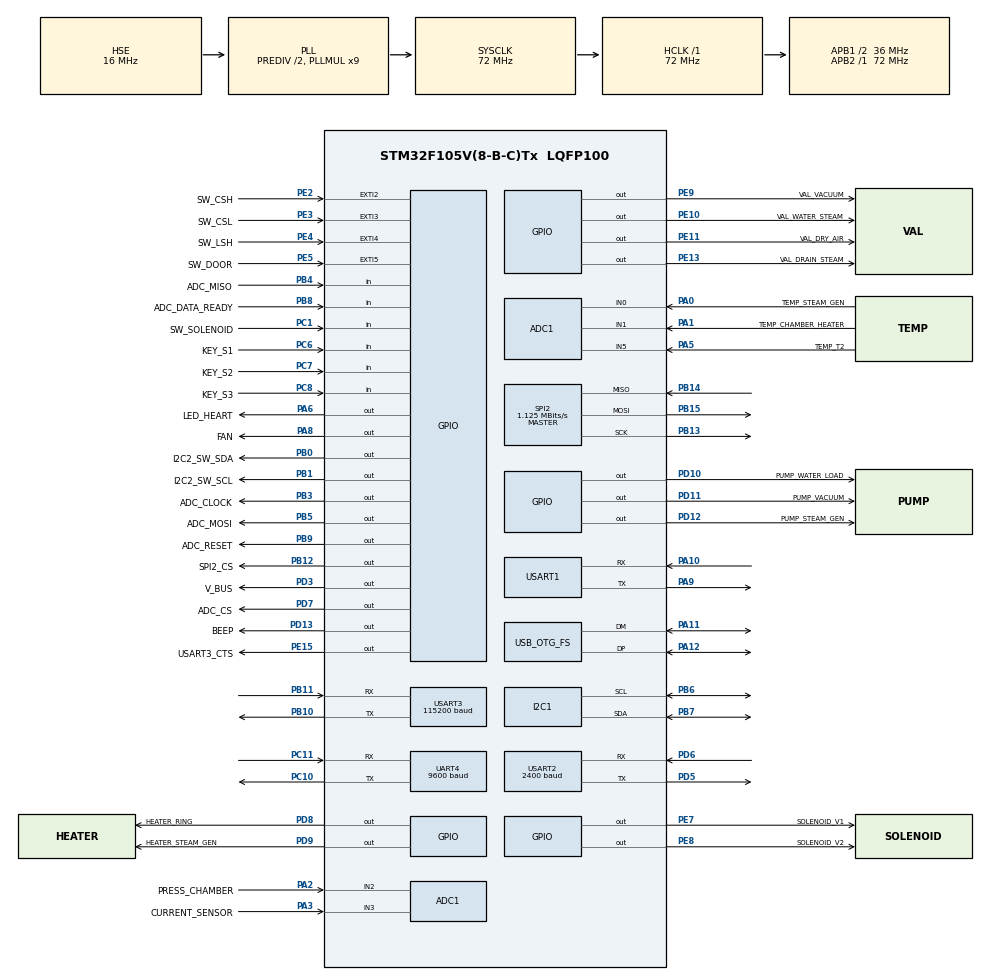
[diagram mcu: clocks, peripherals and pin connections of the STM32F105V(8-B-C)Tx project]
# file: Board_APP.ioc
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ADC1.Channel-0\#ChannelRegularConversion=ADC_CHANNEL_0
ADC1.ContinuousConvMode=DISABLE
ADC1.DiscontinuousConvMode=DISABLE
ADC1.NbrOfConversion=1
ADC1.NbrOfConversionFlag=1
ADC1.Rank-0\#ChannelRegularConversion=1
ADC1.SamplingTime-0\#ChannelRegularConversion=ADC_SAMPLETIME_28CYCLES_5
ADC1.master=1
Dma.Request0=USART1_RX
Dma.Request1=USART3_RX
Dma.Request2=USART3_TX
Dma.USART1_RX.0.Direction=DMA_PERIPH_TO_MEMORY
Dma.USART1_RX.0.Instance=DMA1_Channel5
Dma.USART1_RX.0.MemDataAlignment=DMA_MDATAALIGN_BYTE
Dma.USART1_RX.0.MemInc=DMA_MINC_ENABLE
Dma.USART1_RX.0.Mode=DMA_NORMAL
Dma.USART1_RX.0.PeriphDataAlignment=DMA_PDATAALIGN_BYTE
Dma.USART1_RX.0.PeriphInc=DMA_PINC_DISABLE
Dma.USART1_RX.0.Priority=DMA_PRIORITY_LOW
Dma.USART3_RX.1.Direction=DMA_PERIPH_TO_MEMORY
Dma.USART3_RX.1.Instance=DMA1_Channel3
Dma.USART3_RX.1.MemDataAlignment=DMA_MDATAALIGN_BYTE
Dma.USART3_RX.1.MemInc=DMA_MINC_ENABLE
Dma.USART3_RX.1.Mode=DMA_CIRCULAR
Dma.USART3_RX.1.PeriphDataAlignment=DMA_PDATAALIGN_BYTE
Dma.USART3_RX.1.PeriphInc=DMA_PINC_DISABLE
Dma.USART3_RX.1.Priority=DMA_PRIORITY_HIGH
Dma.USART3_TX.2.Direction=DMA_MEMORY_TO_PERIPH
Dma.USART3_TX.2.Instance=DMA1_Channel2
Dma.USART3_TX.2.MemDataAlignment=DMA_MDATAALIGN_BYTE
Dma.USART3_TX.2.MemInc=DMA_MINC_ENABLE
Dma.USART3_TX.2.Mode=DMA_CIRCULAR
Dma.USART3_TX.2.PeriphDataAlignment=DMA_PDATAALIGN_BYTE
Dma.USART3_TX.2.PeriphInc=DMA_PINC_DISABLE
Dma.USART3_TX.2.Priority=DMA_PRIORITY_HIGH
FATFS._CODE_PAGE=850
FATFS._FS_REENTRANT=0
FATFS._MAX_LFN=32
FATFS._MAX_SS=4096
FATFS._USE_LFN=1
FREERTOS.BinarySemaphores01=semaphorePower,Dynamic,NULL
FREERTOS.Tasks01=taskAlive,-2,2048,StartTaskAlive,Default,NULL,Dynamic,NULL,NULL
FREERTOS.configTOTAL_HEAP_SIZE=42000
FREERTOS.configUSE_NEWLIB_REENTRANT=1
Mcu.Family=STM32F1
Mcu.Name=STM32F105V(8-B-C)Tx
Mcu.Package=LQFP100
NVIC.DMA1_Channel2_IRQn=true\:5\:0\:false\:false\:true\:true\:false\:true\:true
NVIC.DMA1_Channel3_IRQn=true\:5\:0\:false\:false\:true\:true\:false\:true\:true
NVIC.DMA1_Channel5_IRQn=true\:5\:0\:false\:false\:true\:true\:false\:true\:true
NVIC.EXTI3_IRQn=true\:5\:0\:false\:false\:true\:true\:true\:true\:true
NVIC.EXTI4_IRQn=true\:5\:0\:false\:false\:true\:true\:true\:true\:true
NVIC.EXTI9_5_IRQn=true\:5\:0\:false\:false\:true\:true\:true\:true\:true
NVIC.OTG_FS_IRQn=true\:5\:0\:false\:false\:true\:true\:true\:true\:true
NVIC.PriorityGroup=NVIC_PRIORITYGROUP_4
NVIC.TIM2_IRQn=true\:5\:0\:false\:false\:true\:true\:true\:true\:true
NVIC.TIM3_IRQn=true\:5\:0\:false\:false\:true\:true\:true\:true\:true
NVIC.TIM6_IRQn=true\:0\:0\:true\:false\:true\:false\:false\:true\:true
NVIC.TimeBase=TIM6_IRQn
NVIC.TimeBaseIP=TIM6
OSC_IN.Mode=HSE-External-Oscillator
OSC_IN.Signal=RCC_OSC_IN
OSC_OUT.Mode=HSE-External-Oscillator
OSC_OUT.Signal=RCC_OSC_OUT
PA0-WKUP.GPIO_Label=TEMP_STEAM_GEN
PA0-WKUP.Signal=ADCx_IN0
PA1.GPIO_Label=TEMP_CHAMBER_HEATER
PA1.Signal=ADCx_IN1
PA10.Mode=Asynchronous
PA10.Signal=USART1_RX
PA11.Mode=Host_Only
PA11.Signal=USB_OTG_FS_DM
PA12.Mode=Host_Only
PA12.Signal=USB_OTG_FS_DP
PA13.Mode=Serial_Wire
PA13.Signal=SYS_JTMS-SWDIO
PA14.Mode=Serial_Wire
PA14.Signal=SYS_JTCK-SWCLK
PA2.GPIO_Label=PRESS_CHAMBER
PA2.Signal=ADCx_IN2
PA3.GPIO_Label=CURRENT_SENSOR
PA3.Signal=ADCx_IN3
PA5.GPIO_Label=TEMP_T2
PA5.Signal=ADCx_IN5
PA6.GPIO_Label=LED_HEART
PA6.Signal=GPIO_Output
PA8.GPIO_Label=FAN
PA8.Signal=GPIO_Output
PA9.Mode=Asynchronous
PA9.Signal=USART1_TX
PB0.GPIO_Label=I2C2_SW_SDA
PB0.Signal=GPIO_Output
PB1.GPIO_Label=I2C2_SW_SCL
PB1.Signal=GPIO_Output
PB10.Mode=Asynchronous
PB10.Signal=USART3_TX
PB11.Mode=Asynchronous
PB11.Signal=USART3_RX
PB12.GPIO_Label=SPI2_CS
PB12.Signal=GPIO_Output
PB13.Mode=Full_Duplex_Master
PB13.Signal=SPI2_SCK
PB14.Mode=Full_Duplex_Master
PB14.Signal=SPI2_MISO
PB15.Mode=Full_Duplex_Master
PB15.Signal=SPI2_MOSI
PB3.GPIO_Label=ADC_CLOCK
PB3.Signal=GPIO_Output
PB4.GPIO_Label=ADC_MISO
PB4.Signal=GPIO_Input
PB5.GPIO_Label=ADC_MOSI
PB5.Signal=GPIO_Output
PB6.Mode=I2C
PB6.Signal=I2C1_SCL
PB7.Mode=I2C
PB7.Signal=I2C1_SDA
PB8.GPIO_Label=ADC_DATA_READY
PB8.Signal=GPIO_Input
PB9.GPIO_Label=ADC_RESET
PB9.Signal=GPIO_Output
PC1.GPIO_Label=SW_SOLENOID
PC1.Signal=GPIO_Input
PC10.Mode=Asynchronous
PC10.Signal=UART4_TX
PC11.Mode=Asynchronous
PC11.Signal=UART4_RX
PC6.GPIO_Label=KEY_S1
PC6.GPIO_PuPd=GPIO_PULLUP
PC6.Signal=GPIO_Input
PC7.GPIO_Label=KEY_S2
PC7.GPIO_PuPd=GPIO_PULLUP
PC7.Signal=GPIO_Input
PC8.GPIO_Label=KEY_S3
PC8.GPIO_PuPd=GPIO_PULLUP
PC8.Signal=GPIO_Input
PD10.GPIO_Label=PUMP_WATER_LOAD
PD10.Signal=GPIO_Output
PD11.GPIO_Label=PUMP_VACUUM
PD11.Signal=GPIO_Output
PD12.GPIO_Label=PUMP_STEAM_GEN
PD12.Signal=GPIO_Output
PD13.GPIO_Label=BEEP
PD13.Signal=GPIO_Output
PD3.GPIO_Label=V_BUS
PD3.Signal=GPIO_Output
PD5.Mode=Asynchronous
PD5.Signal=USART2_TX
PD6.Mode=Asynchronous
PD6.Signal=USART2_RX
PD7.GPIO_Label=ADC_CS
PD7.Signal=GPIO_Output
PD8.GPIO_Label=HEATER_RING
PD8.Signal=GPIO_Output
PD9.GPIO_Label=HEATER_STEAM_GEN
PD9.Signal=GPIO_Output
PE10.GPIO_Label=VAL_WATER_STEAM
PE10.Signal=GPIO_Output
PE11.GPIO_Label=VAL_DRY_AIR
PE11.Signal=GPIO_Output
PE13.GPIO_Label=VAL_DRAIN_STEAM
PE13.Signal=GPIO_Output
PE15.GPIO_Label=USART3_CTS
PE15.Signal=GPIO_Output
PE2.GPIO_Label=SW_CSH
PE2.GPIO_ModeDefaultEXTI=GPIO_MODE_IT_RISING_FALLING
PE2.Signal=GPXTI2
PE3.GPIO_Label=SW_CSL
PE3.GPIO_ModeDefaultEXTI=GPIO_MODE_IT_RISING_FALLING
PE3.Signal=GPXTI3
PE4.GPIO_Label=SW_LSH
PE4.GPIO_ModeDefaultEXTI=GPIO_MODE_IT_RISING_FALLING
PE4.Signal=GPXTI4
PE5.GPIO_Label=SW_DOOR
PE5.GPIO_ModeDefaultEXTI=GPIO_MODE_IT_RISING_FALLING
PE5.Signal=GPXTI5
PE7.GPIO_Label=SOLENOID_V1
PE7.Signal=GPIO_Output
PE8.GPIO_Label=SOLENOID_V2
PE8.Signal=GPIO_Output
PE9.GPIO_Label=VAL_VACUUM
PE9.Signal=GPIO_Output
ProjectManager.HeapSize=0x200
ProjectManager.StackSize=0x400
ProjectManager.TargetToolchain=STM32CubeIDE
RCC.ADCPresc=RCC_ADCPCLK2_DIV6
RCC.AHBFreq_Value=72000000
RCC.APB1CLKDivider=RCC_HCLK_DIV2
RCC.APB1Freq_Value=36000000
RCC.APB1TimFreq_Value=72000000
RCC.APB2Freq_Value=72000000
RCC.APB2TimFreq_Value=72000000
RCC.HCLKFreq_Value=72000000
RCC.HSEDivPLL=RCC_HSE_PREDIV_DIV2
RCC.HSE_VALUE=16000000
RCC.PLLMUL=RCC_PLL_MUL9
RCC.PLLSourceVirtual=RCC_PLLSOURCE_HSE
RCC.SYSCLKFreq_VALUE=72000000
RCC.SYSCLKSource=RCC_SYSCLKSOURCE_PLLCLK
RCC.USBFreq_Value=48000000
SH.ADCx_IN0.0=ADC1_IN0,IN0
SH.ADCx_IN1.0=ADC1_IN1,IN1
SH.ADCx_IN2.0=ADC1_IN2,IN2
SH.ADCx_IN3.0=ADC1_IN3,IN3
SH.ADCx_IN5.0=ADC1_IN5,IN5
SPI2.BaudRatePrescaler=SPI_BAUDRATEPRESCALER_32
SPI2.CalculateBaudRate=1.125 MBits/s
SPI2.Direction=SPI_DIRECTION_2LINES
SPI2.Mode=SPI_MODE_MASTER
SPI2.VirtualType=VM_MASTER
TIM2.AutoReloadPreload=TIM_AUTORELOAD_PRELOAD_DISABLE
TIM2.Period=7200
TIM2.Prescaler=10000
TIM3.Prescaler=10000
UART4.BaudRate=9600
UART4.VirtualMode=Asynchronous
USART1.VirtualMode=VM_ASYNC
USART2.BaudRate=2400
USART2.VirtualMode=VM_ASYNC
USART3.BaudRate=115200
USART3.Mode=MODE_TX_RX
USART3.VirtualMode=VM_ASYNC
USB_HOST.BSP.number=1
USB_HOST.USBH_HandleTypeDef=hUsbHostFS
USB_HOST.USBH_PROCESS_PRIO=osPriorityHigh
USB_HOST.USBH_PROCESS_STACK_SIZE=2048
USB_HOST.VirtualModeFS=Msc
USB_HOST0.BSP.STBoard=false
USB_HOST0.BSP.api=Unknown
USB_HOST0.BSP.instance=PD3
USB_HOST0.BSP.ip=GPIO
USB_HOST0.BSP.mode=Output
USB_HOST0.BSP.name=Drive_VBUS_FS
USB_HOST0.BSP.solution=PD3
USB_OTG_FS.VirtualMode=Host_Only
VP_FATFS_VS_USB.Mode=USB
VP_FREERTOS_VS_CMSIS_V1.Mode=CMSIS_V1
VP_SYS_VS_tim6.Mode=TIM6
VP_TIM2_VS_ClockSourceINT.Mode=Internal
VP_TIM3_VS_ClockSourceINT.Mode=Internal
VP_USB_HOST_VS_USB_HOST_MSC_FS.Mode=MSC_FS
board=custom

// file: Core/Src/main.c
/* USER CODE BEGIN Header */
/**
  ******************************************************************************
  * @file           : main.c
  * @brief          : Main program body
  ******************************************************************************
  * @attention
  *
  * Copyright (c) 2022 STMicroelectronics.
  * All rights reserved.
  *
  * This software is licensed under terms that can be found in the LICENSE file
  * in the root directory of this software component.
  * If no LICENSE file comes with this software, it is provided AS-IS.
  *
  ******************************************************************************
  */
/* USER CODE END Header */
#include "main.h"
#include "cmsis_os.h"
#include "fatfs.h"
#include "usb_host.h"

/* USER CODE BEGIN Includes */
#include "system.h"
#include "keys.h"
#include "sensors.h"
#include <stdio.h>
/* USER CODE END Includes */

ADC_HandleTypeDef hadc1;

I2C_HandleTypeDef hi2c1;

SPI_HandleTypeDef hspi2;

TIM_HandleTypeDef htim2;
TIM_HandleTypeDef htim3;

UART_HandleTypeDef huart4;
UART_HandleTypeDef huart1;
UART_HandleTypeDef huart2;
UART_HandleTypeDef huart3;
DMA_HandleTypeDef hdma_usart1_rx;
DMA_HandleTypeDef hdma_usart3_rx;
DMA_HandleTypeDef hdma_usart3_tx;

osThreadId taskAliveHandle;
osSemaphoreId semaphorePowerHandle;

void SystemClock_Config(void);
static void MX_GPIO_Init(void);
static void MX_DMA_Init(void);
static void MX_USART3_UART_Init(void);
static void MX_I2C1_Init(void);
static void MX_SPI2_Init(void);
static void MX_USART1_UART_Init(void);
static void MX_UART4_Init(void);
static void MX_ADC1_Init(void);
static void MX_USART2_UART_Init(void);
static void MX_TIM2_Init(void);
static void MX_TIM3_Init(void);
void StartTaskAlive(void const * argument);

int main(void)
{

  /* MCU Configuration--------------------------------------------------------*/

  /* Reset of all peripherals, Initializes the Flash interface and the Systick. */
  HAL_Init();

  /* Configure the system clock */
  SystemClock_Config();

  /* Initialize all configured peripherals */
  MX_GPIO_Init();
  MX_DMA_Init();
  MX_USART3_UART_Init();
  MX_I2C1_Init();
  MX_SPI2_Init();
  MX_USART1_UART_Init();
  MX_UART4_Init();
  MX_ADC1_Init();
  MX_USART2_UART_Init();
  MX_TIM2_Init();
  MX_TIM3_Init();
  MX_FATFS_Init();

  /* Create the semaphores(s) */
  /* definition and creation of semaphorePower */
  osSemaphoreDef(semaphorePower);
  semaphorePowerHandle = osSemaphoreCreate(osSemaphore(semaphorePower), 1);

  /* Create the thread(s) */
  /* definition and creation of taskAlive */
  osThreadDef(taskAlive, StartTaskAlive, osPriorityLow, 0, 2048);
  taskAliveHandle = osThreadCreate(osThread(taskAlive), NULL);

  /* Start scheduler */
  osKernelStart();

  /* We should never get here as control is now taken by the scheduler */

  /* Infinite loop */
  while (1)
  {

  }
}

void SystemClock_Config(void)
{
  RCC_OscInitTypeDef RCC_OscInitStruct = {0};
  RCC_ClkInitTypeDef RCC_ClkInitStruct = {0};
  RCC_PeriphCLKInitTypeDef PeriphClkInit = {0};

  /** Initializes the RCC Oscillators according to the specified parameters
  * in the RCC_OscInitTypeDef structure.
  */
  RCC_OscInitStruct.OscillatorType = RCC_OSCILLATORTYPE_HSE;
  RCC_OscInitStruct.HSEState = RCC_HSE_ON;
  RCC_OscInitStruct.HSEPredivValue = RCC_HSE_PREDIV_DIV2;
  RCC_OscInitStruct.HSIState = RCC_HSI_ON;
  RCC_OscInitStruct.Prediv1Source = RCC_PREDIV1_SOURCE_HSE;
  RCC_OscInitStruct.PLL.PLLState = RCC_PLL_ON;
  RCC_OscInitStruct.PLL.PLLSource = RCC_PLLSOURCE_HSE;
  RCC_OscInitStruct.PLL.PLLMUL = RCC_PLL_MUL9;
  RCC_OscInitStruct.PLL2.PLL2State = RCC_PLL_NONE;
  if (HAL_RCC_OscConfig(&RCC_OscInitStruct) != HAL_OK)
  {
    Error_Handler();
  }

  /** Initializes the CPU, AHB and APB buses clocks
  */
  RCC_ClkInitStruct.ClockType = RCC_CLOCKTYPE_HCLK|RCC_CLOCKTYPE_SYSCLK
                              |RCC_CLOCKTYPE_PCLK1|RCC_CLOCKTYPE_PCLK2;
  RCC_ClkInitStruct.SYSCLKSource = RCC_SYSCLKSOURCE_PLLCLK;
  RCC_ClkInitStruct.AHBCLKDivider = RCC_SYSCLK_DIV1;
  RCC_ClkInitStruct.APB1CLKDivider = RCC_HCLK_DIV2;
  RCC_ClkInitStruct.APB2CLKDivider = RCC_HCLK_DIV1;

  if (HAL_RCC_ClockConfig(&RCC_ClkInitStruct, FLASH_LATENCY_2) != HAL_OK)
  {
    Error_Handler();
  }
  PeriphClkInit.PeriphClockSelection = RCC_PERIPHCLK_ADC|RCC_PERIPHCLK_USB;
  PeriphClkInit.AdcClockSelection = RCC_ADCPCLK2_DIV6;
  PeriphClkInit.UsbClockSelection = RCC_USBCLKSOURCE_PLL_DIV3;
  if (HAL_RCCEx_PeriphCLKConfig(&PeriphClkInit) != HAL_OK)
  {
    Error_Handler();
  }

  /** Configure the Systick interrupt time
  */
  __HAL_RCC_PLLI2S_ENABLE();
}

static void MX_ADC1_Init(void)
{

  ADC_ChannelConfTypeDef sConfig = {0};

  /** Common config
  */
  hadc1.Instance = ADC1;
  hadc1.Init.ScanConvMode = ADC_SCAN_DISABLE;
  hadc1.Init.ContinuousConvMode = DISABLE;
  hadc1.Init.DiscontinuousConvMode = DISABLE;
  hadc1.Init.ExternalTrigConv = ADC_SOFTWARE_START;
  hadc1.Init.DataAlign = ADC_DATAALIGN_RIGHT;
  hadc1.Init.NbrOfConversion = 1;
  if (HAL_ADC_Init(&hadc1) != HAL_OK)
  {
    Error_Handler();
  }

  /** Configure Regular Channel
  */
  sConfig.Channel = ADC_CHANNEL_0;
  sConfig.Rank = ADC_REGULAR_RANK_1;
  sConfig.SamplingTime = ADC_SAMPLETIME_28CYCLES_5;
  if (HAL_ADC_ConfigChannel(&hadc1, &sConfig) != HAL_OK)
  {
    Error_Handler();
  }

}

static void MX_I2C1_Init(void)
{

  hi2c1.Instance = I2C1;
  hi2c1.Init.ClockSpeed = 100000;
  hi2c1.Init.DutyCycle = I2C_DUTYCYCLE_2;
  hi2c1.Init.OwnAddress1 = 0;
  hi2c1.Init.AddressingMode = I2C_ADDRESSINGMODE_7BIT;
  hi2c1.Init.DualAddressMode = I2C_DUALADDRESS_DISABLE;
  hi2c1.Init.OwnAddress2 = 0;
  hi2c1.Init.GeneralCallMode = I2C_GENERALCALL_DISABLE;
  hi2c1.Init.NoStretchMode = I2C_NOSTRETCH_DISABLE;
  if (HAL_I2C_Init(&hi2c1) != HAL_OK)
  {
    Error_Handler();
  }

}

static void MX_SPI2_Init(void)
{

  /* SPI2 parameter configuration*/
  hspi2.Instance = SPI2;
  hspi2.Init.Mode = SPI_MODE_MASTER;
  hspi2.Init.Direction = SPI_DIRECTION_2LINES;
  hspi2.Init.DataSize = SPI_DATASIZE_8BIT;
  hspi2.Init.CLKPolarity = SPI_POLARITY_LOW;
  hspi2.Init.CLKPhase = SPI_PHASE_1EDGE;
  hspi2.Init.NSS = SPI_NSS_SOFT;
  hspi2.Init.BaudRatePrescaler = SPI_BAUDRATEPRESCALER_32;
  hspi2.Init.FirstBit = SPI_FIRSTBIT_MSB;
  hspi2.Init.TIMode = SPI_TIMODE_DISABLE;
  hspi2.Init.CRCCalculation = SPI_CRCCALCULATION_DISABLE;
  hspi2.Init.CRCPolynomial = 10;
  if (HAL_SPI_Init(&hspi2) != HAL_OK)
  {
    Error_Handler();
  }

}

static void MX_TIM2_Init(void)
{

  TIM_ClockConfigTypeDef sClockSourceConfig = {0};
  TIM_MasterConfigTypeDef sMasterConfig = {0};

  htim2.Instance = TIM2;
  htim2.Init.Prescaler = 10000;
  htim2.Init.CounterMode = TIM_COUNTERMODE_UP;
  htim2.Init.Period = 7200;
  htim2.Init.ClockDivision = TIM_CLOCKDIVISION_DIV1;
  htim2.Init.AutoReloadPreload = TIM_AUTORELOAD_PRELOAD_DISABLE;
  if (HAL_TIM_Base_Init(&htim2) != HAL_OK)
  {
    Error_Handler();
  }
  sClockSourceConfig.ClockSource = TIM_CLOCKSOURCE_INTERNAL;
  if (HAL_TIM_ConfigClockSource(&htim2, &sClockSourceConfig) != HAL_OK)
  {
    Error_Handler();
  }
  sMasterConfig.MasterOutputTrigger = TIM_TRGO_RESET;
  sMasterConfig.MasterSlaveMode = TIM_MASTERSLAVEMODE_DISABLE;
  if (HAL_TIMEx_MasterConfigSynchronization(&htim2, &sMasterConfig) != HAL_OK)
  {
    Error_Handler();
  }

}

static void MX_TIM3_Init(void)
{

  TIM_ClockConfigTypeDef sClockSourceConfig = {0};
  TIM_MasterConfigTypeDef sMasterConfig = {0};

  htim3.Instance = TIM3;
  htim3.Init.Prescaler = 10000;
  htim3.Init.CounterMode = TIM_COUNTERMODE_UP;
  htim3.Init.Period = 65535;
  htim3.Init.ClockDivision = TIM_CLOCKDIVISION_DIV1;
  htim3.Init.AutoReloadPreload = TIM_AUTORELOAD_PRELOAD_DISABLE;
  if (HAL_TIM_Base_Init(&htim3) != HAL_OK)
  {
    Error_Handler();
  }
  sClockSourceConfig.ClockSource = TIM_CLOCKSOURCE_INTERNAL;
  if (HAL_TIM_ConfigClockSource(&htim3, &sClockSourceConfig) != HAL_OK)
  {
    Error_Handler();
  }
  sMasterConfig.MasterOutputTrigger = TIM_TRGO_RESET;
  sMasterConfig.MasterSlaveMode = TIM_MASTERSLAVEMODE_DISABLE;
  if (HAL_TIMEx_MasterConfigSynchronization(&htim3, &sMasterConfig) != HAL_OK)
  {
    Error_Handler();
  }

}

static void MX_UART4_Init(void)
{

  huart4.Instance = UART4;
  huart4.Init.BaudRate = 9600;
  huart4.Init.WordLength = UART_WORDLENGTH_8B;
  huart4.Init.StopBits = UART_STOPBITS_1;
  huart4.Init.Parity = UART_PARITY_NONE;
  huart4.Init.Mode = UART_MODE_TX_RX;
  huart4.Init.HwFlowCtl = UART_HWCONTROL_NONE;
  huart4.Init.OverSampling = UART_OVERSAMPLING_16;
  if (HAL_UART_Init(&huart4) != HAL_OK)
  {
    Error_Handler();
  }

}

static void MX_USART1_UART_Init(void)
{

  huart1.Instance = USART1;
  huart1.Init.BaudRate = 115200;
  huart1.Init.WordLength = UART_WORDLENGTH_8B;
  huart1.Init.StopBits = UART_STOPBITS_1;
  huart1.Init.Parity = UART_PARITY_NONE;
  huart1.Init.Mode = UART_MODE_TX_RX;
  huart1.Init.HwFlowCtl = UART_HWCONTROL_NONE;
  huart1.Init.OverSampling = UART_OVERSAMPLING_16;
  if (HAL_UART_Init(&huart1) != HAL_OK)
  {
    Error_Handler();
  }

}

static void MX_USART2_UART_Init(void)
{

  huart2.Instance = USART2;
  huart2.Init.BaudRate = 2400;
  huart2.Init.WordLength = UART_WORDLENGTH_8B;
  huart2.Init.StopBits = UART_STOPBITS_1;
  huart2.Init.Parity = UART_PARITY_NONE;
  huart2.Init.Mode = UART_MODE_TX_RX;
  huart2.Init.HwFlowCtl = UART_HWCONTROL_NONE;
  huart2.Init.OverSampling = UART_OVERSAMPLING_16;
  if (HAL_UART_Init(&huart2) != HAL_OK)
  {
    Error_Handler();
  }

}

static void MX_USART3_UART_Init(void)
{

  huart3.Instance = USART3;
  huart3.Init.BaudRate = 115200;
  huart3.Init.WordLength = UART_WORDLENGTH_8B;
  huart3.Init.StopBits = UART_STOPBITS_1;
  huart3.Init.Parity = UART_PARITY_NONE;
  huart3.Init.Mode = UART_MODE_TX_RX;
  huart3.Init.HwFlowCtl = UART_HWCONTROL_NONE;
  huart3.Init.OverSampling = UART_OVERSAMPLING_16;
  if (HAL_UART_Init(&huart3) != HAL_OK)
  {
    Error_Handler();
  }

}

static void MX_DMA_Init(void)
{

  /* DMA controller clock enable */
  __HAL_RCC_DMA1_CLK_ENABLE();

  /* DMA interrupt init */
  /* DMA1_Channel2_IRQn interrupt configuration */
  HAL_NVIC_SetPriority(DMA1_Channel2_IRQn, 5, 0);
  HAL_NVIC_EnableIRQ(DMA1_Channel2_IRQn);
  /* DMA1_Channel3_IRQn interrupt configuration */
  HAL_NVIC_SetPriority(DMA1_Channel3_IRQn, 5, 0);
  HAL_NVIC_EnableIRQ(DMA1_Channel3_IRQn);
  /* DMA1_Channel5_IRQn interrupt configuration */
  HAL_NVIC_SetPriority(DMA1_Channel5_IRQn, 5, 0);
  HAL_NVIC_EnableIRQ(DMA1_Channel5_IRQn);

}

static void MX_GPIO_Init(void)
{
  GPIO_InitTypeDef GPIO_InitStruct = {0};

  /* GPIO Ports Clock Enable */
  __HAL_RCC_GPIOE_CLK_ENABLE();
  __HAL_RCC_GPIOC_CLK_ENABLE();
  __HAL_RCC_GPIOA_CLK_ENABLE();
  __HAL_RCC_GPIOB_CLK_ENABLE();
  __HAL_RCC_GPIOD_CLK_ENABLE();

  /*Configure GPIO pin Output Level */
  HAL_GPIO_WritePin(GPIOA, LED_HEART_Pin|FAN_Pin, GPIO_PIN_RESET);

  /*Configure GPIO pin Output Level */
  HAL_GPIO_WritePin(GPIOB, I2C2_SW_SDA_Pin|I2C2_SW_SCL_Pin|SPI2_CS_Pin|ADC_CLOCK_Pin
                          |ADC_MOSI_Pin|ADC_RESET_Pin, GPIO_PIN_RESET);

  /*Configure GPIO pin Output Level */
  HAL_GPIO_WritePin(GPIOE, SOLENOID_V1_Pin|SOLENOID_V2_Pin|VAL_VACUUM_Pin|VAL_WATER_STEAM_Pin
                          |VAL_DRY_AIR_Pin|VAL_DRAIN_STEAM_Pin|USART3_CTS_Pin, GPIO_PIN_RESET);

  /*Configure GPIO pin Output Level */
  HAL_GPIO_WritePin(GPIOD, HEATER_RING_Pin|HEATER_STEAM_GEN_Pin|PUMP_WATER_LOAD_Pin|PUMP_VACUUM_Pin
                          |PUMP_STEAM_GEN_Pin|BEEP_Pin|V_BUS_Pin|ADC_CS_Pin, GPIO_PIN_RESET);

  /*Configure GPIO pins : SW_CSH_Pin SW_CSL_Pin SW_LSH_Pin SW_DOOR_Pin */
  GPIO_InitStruct.Pin = SW_CSH_Pin|SW_CSL_Pin|SW_LSH_Pin|SW_DOOR_Pin;
  GPIO_InitStruct.Mode = GPIO_MODE_IT_RISING_FALLING;
  GPIO_InitStruct.Pull = GPIO_NOPULL;
  HAL_GPIO_Init(GPIOE, &GPIO_InitStruct);

  /*Configure GPIO pin : SW_SOLENOID_Pin */
  GPIO_InitStruct.Pin = SW_SOLENOID_Pin;
  GPIO_InitStruct.Mode = GPIO_MODE_INPUT;
  GPIO_InitStruct.Pull = GPIO_NOPULL;
  HAL_GPIO_Init(SW_SOLENOID_GPIO_Port, &GPIO_InitStruct);

  /*Configure GPIO pins : LED_HEART_Pin FAN_Pin */
  GPIO_InitStruct.Pin = LED_HEART_Pin|FAN_Pin;
  GPIO_InitStruct.Mode = GPIO_MODE_OUTPUT_PP;
  GPIO_InitStruct.Pull = GPIO_NOPULL;
  GPIO_InitStruct.Speed = GPIO_SPEED_FREQ_LOW;
  HAL_GPIO_Init(GPIOA, &GPIO_InitStruct);

  /*Configure GPIO pins : I2C2_SW_SDA_Pin I2C2_SW_SCL_Pin SPI2_CS_Pin ADC_CLOCK_Pin
                           ADC_MOSI_Pin ADC_RESET_Pin */
  GPIO_InitStruct.Pin = I2C2_SW_SDA_Pin|I2C2_SW_SCL_Pin|SPI2_CS_Pin|ADC_CLOCK_Pin
                          |ADC_MOSI_Pin|ADC_RESET_Pin;
  GPIO_InitStruct.Mode = GPIO_MODE_OUTPUT_PP;
  GPIO_InitStruct.Pull = GPIO_NOPULL;
  GPIO_InitStruct.Speed = GPIO_SPEED_FREQ_LOW;
  HAL_GPIO_Init(GPIOB, &GPIO_InitStruct);

  /*Configure GPIO pins : SOLENOID_V1_Pin SOLENOID_V2_Pin VAL_VACUUM_Pin VAL_WATER_STEAM_Pin
                           VAL_DRY_AIR_Pin VAL_DRAIN_STEAM_Pin USART3_CTS_Pin */
  GPIO_InitStruct.Pin = SOLENOID_V1_Pin|SOLENOID_V2_Pin|VAL_VACUUM_Pin|VAL_WATER_STEAM_Pin
                          |VAL_DRY_AIR_Pin|VAL_DRAIN_STEAM_Pin|USART3_CTS_Pin;
  GPIO_InitStruct.Mode = GPIO_MODE_OUTPUT_PP;
  GPIO_InitStruct.Pull = GPIO_NOPULL;
  GPIO_InitStruct.Speed = GPIO_SPEED_FREQ_LOW;
  HAL_GPIO_Init(GPIOE, &GPIO_InitStruct);

  /*Configure GPIO pins : HEATER_RING_Pin HEATER_STEAM_GEN_Pin PUMP_WATER_LOAD_Pin PUMP_VACUUM_Pin
                           PUMP_STEAM_GEN_Pin BEEP_Pin V_BUS_Pin ADC_CS_Pin */
  GPIO_InitStruct.Pin = HEATER_RING_Pin|HEATER_STEAM_GEN_Pin|PUMP_WATER_LOAD_Pin|PUMP_VACUUM_Pin
                          |PUMP_STEAM_GEN_Pin|BEEP_Pin|V_BUS_Pin|ADC_CS_Pin;
  GPIO_InitStruct.Mode = GPIO_MODE_OUTPUT_PP;
  GPIO_InitStruct.Pull = GPIO_NOPULL;
  GPIO_InitStruct.Speed = GPIO_SPEED_FREQ_LOW;
  HAL_GPIO_Init(GPIOD, &GPIO_InitStruct);

  /*Configure GPIO pins : KEY_S1_Pin KEY_S2_Pin KEY_S3_Pin */
  GPIO_InitStruct.Pin = KEY_S1_Pin|KEY_S2_Pin|KEY_S3_Pin;
  GPIO_InitStruct.Mode = GPIO_MODE_INPUT;
  GPIO_InitStruct.Pull = GPIO_PULLUP;
  HAL_GPIO_Init(GPIOC, &GPIO_InitStruct);

  /*Configure GPIO pins : ADC_MISO_Pin ADC_DATA_READY_Pin */
  GPIO_InitStruct.Pin = ADC_MISO_Pin|ADC_DATA_READY_Pin;
  GPIO_InitStruct.Mode = GPIO_MODE_INPUT;
  GPIO_InitStruct.Pull = GPIO_NOPULL;
  HAL_GPIO_Init(GPIOB, &GPIO_InitStruct);

  /* EXTI interrupt init*/
  HAL_NVIC_SetPriority(EXTI3_IRQn, 5, 0);
  HAL_NVIC_EnableIRQ(EXTI3_IRQn);

  HAL_NVIC_SetPriority(EXTI4_IRQn, 5, 0);
  HAL_NVIC_EnableIRQ(EXTI4_IRQn);

  HAL_NVIC_SetPriority(EXTI9_5_IRQn, 5, 0);
  HAL_NVIC_EnableIRQ(EXTI9_5_IRQn);

}

void StartTaskAlive(void const * argument)
{
  /* init code for USB_HOST */
  MX_USB_HOST_Init();
  /* USER CODE BEGIN 5 */
  /* Infinite loop */
	SysInit();

//	  MX_IWDG_Init();
	for(;;)	{
		HAL_GPIO_TogglePin(LED_HEART_GPIO_Port, LED_HEART_Pin);
//		HAL_IWDG_Refresh(&hiwdg);
		osDelay(200);
	}
  /* USER CODE END 5 */
}

void HAL_TIM_PeriodElapsedCallback(TIM_HandleTypeDef *htim)
{
  /* USER CODE BEGIN Callback 0 */
////	if (htim->Instance == TIM2) {
//////		osSemaphoreWait(semaphorePowerHandle, osWaitForever);
////		PWMHeaterChamber();
//////		osSemaphoreRelease(semaphorePowerHandle);
//
//	}
//	if (htim->Instance == TIM3) {
////		osSemaphoreWait(semaphorePowerHandle, osWaitForever);
//		PWMHeaterSteamGenerator();
////		osSemaphoreRelease(semaphorePowerHandle);
//	}
  /* USER CODE END Callback 0 */
  if (htim->Instance == TIM6)
  {
    HAL_IncTick();
  }
}

void Error_Handler(void)
{
  __disable_irq();
  while (1)
  {
  }
}
